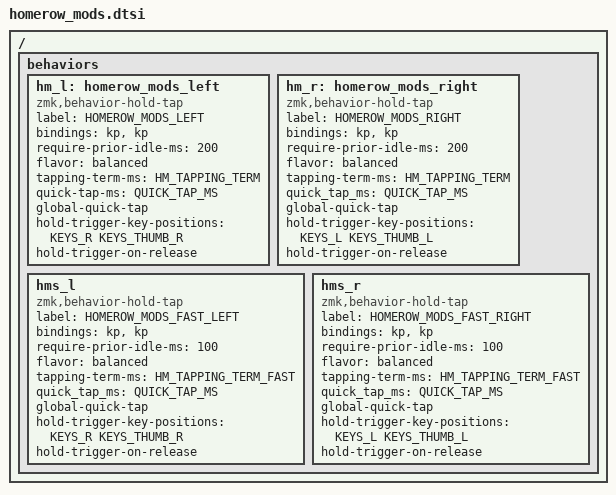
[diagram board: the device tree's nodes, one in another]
#include "./corne_keys.h"

#define QUICK_TAP_MS 200
#define HM_TAPPING_TERM 200
#define HM_TAPPING_TERM_FAST 100

/ {

    behaviors {
        hm_l: homerow_mods_left {
            compatible = "zmk,behavior-hold-tap";
            label = "HOMEROW_MODS_LEFT";
            #binding-cells = <2>;
            bindings = <&kp>,  <&kp>;
            require-prior-idle-ms = <200>;
            flavor = "balanced";
            tapping-term-ms = <HM_TAPPING_TERM>;
            quick-tap-ms = <QUICK_TAP_MS>;
            global-quick-tap;
            hold-trigger-key-positions = <KEYS_R KEYS_THUMB_R>;
            hold-trigger-on-release;
        };

        hm_r: homerow_mods_right {
            compatible = "zmk,behavior-hold-tap";
            label = "HOMEROW_MODS_RIGHT";
            #binding-cells = <2>;
            bindings = <&kp>, <&kp>;
            require-prior-idle-ms = <200>;
            flavor = "balanced";
            tapping-term-ms = <HM_TAPPING_TERM>;
            quick_tap_ms = <QUICK_TAP_MS>;
            global-quick-tap;
            hold-trigger-key-positions = <KEYS_L KEYS_THUMB_L>;
            hold-trigger-on-release;
        };


        hms_l: hms_l {
            compatible = "zmk,behavior-hold-tap";
            label = "HOMEROW_MODS_FAST_LEFT";
            #binding-cells = <2>;
            bindings = <&kp>, <&kp>;
            require-prior-idle-ms = <100>;
            flavor = "balanced";
            tapping-term-ms = <HM_TAPPING_TERM_FAST>;
            quick_tap_ms = <QUICK_TAP_MS>;
            global-quick-tap;
            hold-trigger-key-positions = <KEYS_R KEYS_THUMB_R>;
            hold-trigger-on-release;
        };

        hms_r: hms_r {
            compatible = "zmk,behavior-hold-tap";
            label = "HOMEROW_MODS_FAST_RIGHT";
            #binding-cells = <2>;
            bindings = <&kp>, <&kp>;
            require-prior-idle-ms = <100>;
            flavor = "balanced";
            tapping-term-ms = <HM_TAPPING_TERM_FAST>;
            quick_tap_ms = <QUICK_TAP_MS>;
            global-quick-tap;
            hold-trigger-key-positions = <KEYS_L KEYS_THUMB_L>;
            hold-trigger-on-release;
        };
  };
};
